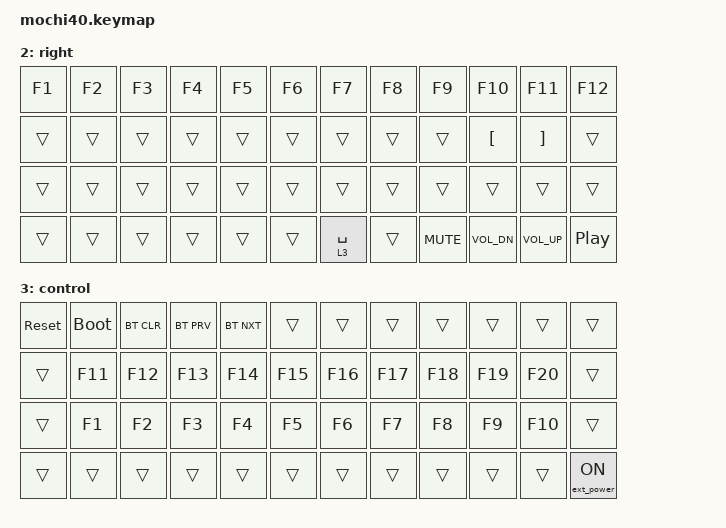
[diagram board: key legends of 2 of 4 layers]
/*
 * Aidan Smith (2021)
 *
 * SPDX-License-Identifier: MIT
 */

#include <behaviors.dtsi>
#include <dt-bindings/zmk/keys.h>
#include <dt-bindings/zmk/bt.h>
#include <dt-bindings/zmk/ext_power.h>

/ {
	keymap {
		compatible = "zmk,keymap";

		default_layer {
			bindings = <
				&kp ESC   &kp Q    &kp W    &kp E    &kp R     &kp T  &kp Y &kp U &kp I     &kp O    &kp P     &kp BSPC
				&kp TAB   &kp A    &kp S    &kp D    &kp F     &kp G  &kp H &kp J &kp K     &kp L    &kp SEMI  &kp RET
				&kp LSHFT &kp Z    &kp X    &kp C    &kp V     &kp B  &kp N &kp M &kp COMMA &kp DOT  &kp FSLH  &kp RSHFT
				&kp LCTL  &kp LGUI &kp LALT &mo 1    &kp SPACE &none  &kp SPACE   &mo 2     &kp LEFT &kp UP    &kp RIGHT
			>;

			sensor-bindings = <&inc_dec_kp C_VOL_DN C_VOL_UP>;
		};

		left {
			bindings = <
				&kp N1    &kp N2 &kp N3 &kp N4 &kp N5 &kp N6 &kp N7 &kp N8    &kp N9    &kp N0    &kp MINUS   &kp EQUAL
				&kp GRAVE &trans &trans &trans &trans &trans &trans &trans    &trans    &trans    &kp SQT     &kp BSLH
				&trans    &trans &trans &trans &trans &trans &trans &trans    &trans    &trans    &kp PSCRN   &trans
				&trans    &trans &trans &trans &trans &trans &trans           &trans    &trans    &kp DOWN    &trans
			>;
		};
		
		right {
			bindings = <
				&kp F1    &kp F2  &kp F3  &kp F4  &kp F5  &kp F6  &kp F7       &kp F8  &kp F9      &kp F10       &kp F11       &kp F12
				&trans    &trans  &trans  &trans  &trans  &trans  &trans       &trans  &trans      &kp LBKT      &kp RBKT      &trans
				&trans    &trans  &trans  &trans  &trans  &trans  &trans       &trans  &trans      &trans        &trans        &trans
				&trans    &trans  &trans  &trans  &trans  &trans  &lt 3 SPACE  &trans  &kp C_MUTE  &kp C_VOL_DN  &kp C_VOL_UP  &kp C_PP
			>;
		};

		control {
			bindings = <
				&sys_reset &bootloader &bt BT_CLR &bt BT_PRV &bt BT_NXT &trans  &trans  &trans  &trans  &trans  &trans  &trans
				&trans     &kp F11     &kp F12    &kp F13    &kp F14    &kp F15 &kp F16 &kp F17 &kp F18 &kp F19 &kp F20 &trans
				&trans     &kp F1      &kp F2     &kp F3     &kp F4     &kp F5  &kp F6  &kp F7  &kp F8  &kp F9  &kp F10 &trans
				&trans     &trans      &trans     &trans     &trans     &trans  &trans  &trans  &trans  &trans  &trans  &ext_power EP_ON
			>;
		};
	};
};
